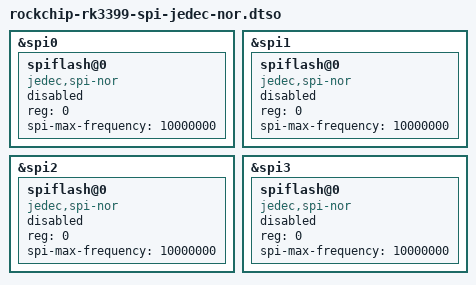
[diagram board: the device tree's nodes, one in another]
/dts-v1/;
/plugin/;

&spi0 {
	#address-cells = <1>; 
	#size-cells = <0>; 
	spiflash@0 { 
		compatible = "jedec,spi-nor"; 
		reg = <0>; 
		spi-max-frequency = <10000000>; 
		status = "disabled"; 
	}; 
};

&spi1 {
	#address-cells = <1>; 
	#size-cells = <0>; 
	spiflash@0 { 
		compatible = "jedec,spi-nor"; 
		reg = <0>; 
		spi-max-frequency = <10000000>; 
		status = "disabled"; 
	}; 
};

&spi2 {
	#address-cells = <1>; 
	#size-cells = <0>; 
	spiflash@0 { 
		compatible = "jedec,spi-nor"; 
		reg = <0>; 
		spi-max-frequency = <10000000>; 
		status = "disabled"; 
	}; 
};

&spi3 {
	#address-cells = <1>; 
	#size-cells = <0>; 
	spiflash@0 { 
		compatible = "jedec,spi-nor"; 
		reg = <0>; 
		spi-max-frequency = <10000000>; 
		status = "disabled"; 
	}; 
};
